AUTOSAR XML (schema 4-2-2)
package /EB/SoftwareComponents
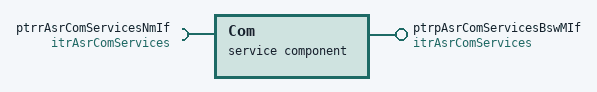
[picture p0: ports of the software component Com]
  service sw component type Com: category=ASR_Interfaces
    provide port ptrpAsrComServicesBswMIf: provided-interface=itrAsrComServices
    require port ptrrAsrComServicesNmIf: required-interface=itrAsrComServices
    behavior Com_IB: handle-termination-and-restart=NO-SUPPORT
      4 x runnable:
        Com_ClearIpduGroupVector
        Com_Init
        Com_IpduGroupControl
        Com_SetIpduGroup
package /EB/TriggerInterfaces
  trigger interface itrAsrComServices
    10 x trigger, all with trigger-period={cse-code=1000, cse-code-factor=0}:
      Com_ClearIpduGroupVector
      Com_Init
      Com_IpduGroupControl
      Com_SetIpduGroup
      NmIf_CbkRxAck_Airbag_01
      NmIf_CbkRxAck_Airbag_02
      NmIf_CbkRxAck_Airbag_eCS_01
      NmIf_CbkRxTOut_Airbag_01
      NmIf_CbkRxTOut_Airbag_02
      NmIf_CbkRxTOut_Airbag_eCS_01
